# PIC32MX274F256B device description
Architecture: MIPS; Family: PIC32MX; Series: PIC32MX
Registers are 32-bit, read-write, no defined reset value unless marked. A register's access mark holds for its fields unless they carry their own. Offsets are from the block's base; [hi:lo] are bit positions; {n}, {i} and the like mark numbered series; 'fields as' and 'values as' point back to an identical list.

## USB
Instances: USB 0x1f885040 in periph2
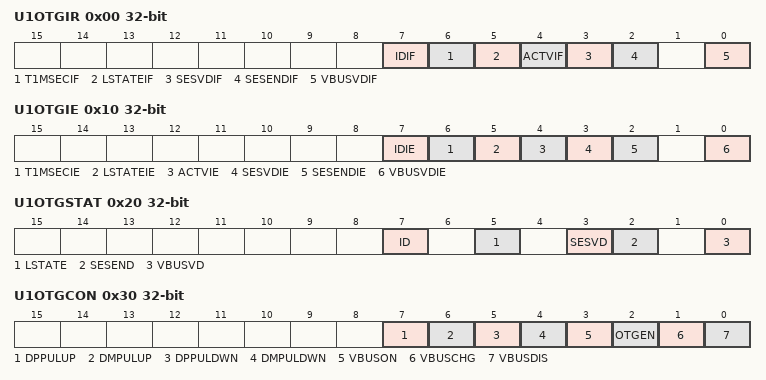
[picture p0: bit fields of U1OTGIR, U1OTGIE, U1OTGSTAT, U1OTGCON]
0x00 U1OTGIR — USB OTG Interrupt Status Register
  [7] IDIF — ID State Change Indicator bit
    1=Change in ID state is detected; 0=No change in ID state is detected
  [6] T1MSECIF — 1 Millisecond Timer bit
    1=1 millisecond timer has expired; 0=1 millisecond timer has not expired
  [5] LSTATEIF — Line State Stable Indicator bit
    1=USB line state has been stable for 1millisecond; 0=USB line state has not been stable for 1 millisecond
  [4] ACTVIF — Bus Activity Indicator bit
    1=Activity on the D+, D-, ID or VBUS pins has caused the device to wake-up; 0=Activity has not been detected
  [3] SESVDIF — Session Valid Change Indicator bit
    1=VBUS voltage has dropped below the session end level; 0=Vbus voltage has not dropped below the session end level
  [2] SESENDIF — B-Device Vbus Change Indicator bit
    1=A change on the session end input was detected; 0=No change on the session end input was detected
  [0] VBUSVDIF — A-Device Vbus Change Indicator bit
    1=Change on the session valid input is detected; 0=No change on the session valid input is detected
0x10 U1OTGIE — USB OTG Interrupt Enable Register
  [7] IDIE — ID Interrupt Enable bit
    1=ID interrupt is enabled; 0=ID interrupt is disabled
  [6] T1MSECIE — 1 Millisecond Timer Interrupt Enable bit
    1=1 millisecond timer interrupt is enabled; 0=1 millisecond timer interrupt is disabled
  [5] LSTATEIE — Line State Interrupt Enable bit
    1=Line state interrupt is enabled; 0=Line state interrupt is disabled
  [4] ACTVIE — Bus Activity Interrupt Enable bit
    1=ACTIVITY interrupt is enabled; 0=ACTIVITY interrupt is disabled
  [3] SESVDIE — Session Valid Interrupt Enable bit
    1=Session valid interrupt is enabled; 0=Session valid interrupt is disabled
  [2] SESENDIE — B-Session End Interrupt Enable bit
    1=B-session end interrupt is enabled; 0=B-session end interrupt is disabled
  [0] VBUSVDIE — A- Vbus Valid Interrupt Enable bit
    1=A-VBUS valid interrupt is enabled; 0=A-VBUS valid interrupt is disabled
0x20 U1OTGSTAT — USB OTG Status Register
  [7] ID — ID Pin State Indicator bit
    1=No cable is attached or a Type-B cable has been plugged into the USB receptacle; 0=A Type-A cable has been plugged into the USB receptacle
  [5] LSTATE — Line State Stable Indicator bit
    1=USB line state (U1CON(SE0) and U1CON(JSTATE)) has been stable for the previous 1 ms; 0=USB line state (U1CON(SE0) and U1CON(JSTATE)) has not been stable for the previous 1 ms
  [3] SESVD — Session Valid Indicator bit
    1=Vbus voltage is above Session Valid on the A or B device; 0=Vbus voltage is below Session Valid on the A or B device
  [2] SESEND — B-Device Session End Indicator bit
    1=Vbus voltage is below Session Valid on the B device; 0=Vbus voltage is above Session Valid on the B device
  [0] VBUSVD — A-Device Vbus Valid Indicator bit
    1=Vbus voltage is above Session Valid on the A device; 0=Vbus voltage is below Session Valid on the A device
0x30 U1OTGCON — USB OTG Control Register
  [7] DPPULUP — D+ Pull-Up Enable bit
    1=D+ data line pull-up resistor is enabled; 0=D+ data line pull-up resistor is disabled
  [6] DMPULUP — D- Pull-Up Enable bit
    1=D- data line pull-up resistor is enabled; 0=D- data line pull-up resistor is disabled
  [5] DPPULDWN — D+ Pull-Down Enable bit
    1=D+ data line pull-down resistor is enabled; 0=D+ data line pull-down resistor is disabled
  [4] DMPULDWN — D- Pull-Down Enable bit
    1=D- data line pull-down resistor is enabled; 0=D- data line pull-down resistor is disabled
  [3] VBUSON — VBUS Power-on bit
    1=VBUS line is powered; 0=VBUS line is not powered
  [2] OTGEN — OTG Functionality Enable bit
    1=DPPULUP, DMPULUP, DPPULDWN and DMPULDWN bits are under software control; 0=DPPULUP, DMPULUP, DPPULDWN and DMPULDWN bits are under USB hardware control
  [1] VBUSCHG — VBUS Charge Enable bit
    1=VBUS line is charged through a pull-up resistor; 0=VBUS line is not charged through a resistor
  [0] VBUSDIS — VBUS Discharge Enable bit
    1=VBUS line is discharged through a pull-down resistor; 0=VBUS line is not discharged through a resistor
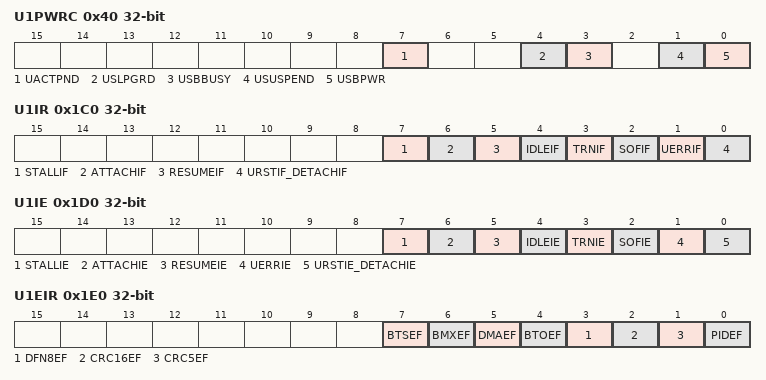
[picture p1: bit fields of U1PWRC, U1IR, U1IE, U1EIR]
0x40 U1PWRC — USB Power Control Register
  [7] UACTPND — USB Activity Pending bit
    1=USB bus activity has been detected; but an interrupt is pending; 0=An interrupt is not pending
  [4] USLPGRD — USB Sleep Entry Guard bit
    1=Sleep entry is blocked if USB bus activity is detected or if a notification is pending; 0=USB module does not block Sleep entry
  [3] USBBUSY — USB Module Busy bit
    1=USB module is active or disabled; 0=USB module is not active and is ready to be enabled
  [1] USUSPEND — USB Suspend Mode bit
    1=USB module is placed in Suspend mode; 0=USB module operates normally
  [0] USBPWR — USB Operation Enable bit
    1=USB module is turned on; 0=USB module is disabled
0x1C0 U1IR — USB Interrupt Register
  [7] STALLIF — STALL Handshake Interrupt bit
    1=(In Host mode) a STALL handshake was received during the handshake phase of the transaction / (In Device mode) a STALL handshake was transmitted during the handshake phase of the transaction; 0=STALL handshake has not been sent
  [6] ATTACHIF — Peripheral Attach Interrupt bit
    1=Peripheral attachment was detected by the USB module; 0=Peripheral attachment was not detected
  [5] RESUMEIF — Resume Interrupt bit
    1=K-State is observed on the D+ or D- pin for 2.5 usec; 0=K-State is not observed
  [4] IDLEIF — Idle Detect Interrupt bit
    1=Idle condition detected (constant Idle state of 3 ms or more); 0=No Idle condition detected
  [3] TRNIF — Token Processing Complete Interrupt bit
    1=Processing of current token is complete; a read of the U1STAT register will provide endpoint information; 0=Processing of current token not complete
  [2] SOFIF — SOF Token Interrupt bit
    1=SOF token received by the peripheral or the SOF threshold reached by the host; 0=SOF token was not received nor threshold reached
  [1] UERRIF — USB Error Condition Interrupt bit
    1=Unmasked error condition has occurred; 0=Unmasked error condition has not occurred
  [0] URSTIF_DETACHIF
0x1D0 U1IE — USB Interrupt Enable Register
  [7] STALLIE — STALL Handshake Interrupt Enable bit
    1=STALL interrupt is enabled; 0=STALL interrupt is disabled
  [6] ATTACHIE — ATTACH Interrupt Enable bit
    1=ATTACH interrupt is enabled; 0=ATTACH interrupt is disabled
  [5] RESUMEIE — RESUME Interrupt Enable bit
    1=RESUME interrupt is enabled; 0=RESUME interrupt is disabled
  [4] IDLEIE — Idle Detect Interrupt Enable bit
    1=Idle interrupt is enabled; 0=Idle interrupt is disabled
  [3] TRNIE — Token Processing Complete Interrupt Enable bit
    1=TRNIF interrupt is enabled; 0=TRNIF interrupt is disabled
  [2] SOFIE — SOF Token Interrupt Enable bit
    1=SOFIF interrupt is enabled; 0=SOFIF interrupt is disabled
  [1] UERRIE — USB Error Interrupt Enable bit
    1=USB Error interrupt is enabled; 0=USB Error interrupt is disabled
  [0] URSTIE_DETACHIE
0x1E0 U1EIR — USB Error Interrupt Status Register
  [7] BTSEF — Bit Stuff Error Flag bit
    1=Packet is rejected due to bit stuff error; 0=Packet is accepted
  [6] BMXEF — Bus Matrix Error Flag bit
    1=The base address, of the BDT, or the address of an individual buffer pointed to by a BDT entry, i s invalid; 0=No address error
  [5] DMAEF — DMA Error Flag bit
    1=USB DMA error condition detected; 0=No DMA error
  [4] BTOEF — Bus Turnaround Time-Out Error Flag bit
    1=Bus turnaround time-out has occurred; 0=No bus turnaround time-out
  [3] DFN8EF — Data Field Size Error Flag bit
    1=Data field received is not an integral number of bytes; 0=Data field received is an integral number of bytes
  [2] CRC16EF — CRC16 Failure Flag bit
    1=Data packet rejected due to CRC16 error; 0=Data packet accepted
  [1] CRC5EF
  [0] PIDEF — PID Check Failure Flag bit
    1=PID check is failed; 0=PID check is passed
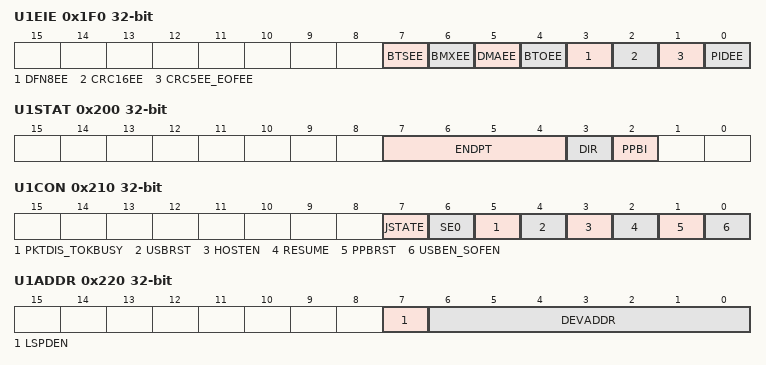
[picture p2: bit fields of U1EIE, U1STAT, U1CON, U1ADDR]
0x1F0 U1EIE — USB Error Interrupt Enable Register
  [7] BTSEE — Bit Stuff Error Interrupt Enable bit
    1=BTSEF interrupt is enabled; 0=BTSEF interrupt is disabled
  [6] BMXEE — Bus Matrix Error Interrupt Enable bit
    1=BMXEF interrupt is enabled; 0=BMXEF interrupt is disabled
  [5] DMAEE — DMA Error Interrupt Enable bit
    1=DMAEF interrupt is enabled; 0=DMAEF interrupt is disabled
  [4] BTOEE — Bus Turnaround Time-out Error Interrupt Enable bit
    1=BTOEF interrupt is enabled; 0=BTOEF interrupt is disabled
  [3] DFN8EE — Data Field Size Error Interrupt Enable bit
    1=DFN8EF interrupt is enabled; 0=DFN8EF interrupt is disabled
  [2] CRC16EE — CRC16 Failure Interrupt Enable bit
    1=CRC16EF interrupt is enabled; 0=CRC16EF interrupt is disabled
  [1] CRC5EE_EOFEE
  [0] PIDEE — PID Check Failure Interrupt Enable bit
    1=PIDEF interrupt is enabled; 0=PIDEF interrupt is disabled
0x200 U1STAT ro — USB Status Register
  [7:4] ENDPT — Encoded Number of Last Endpoint Activity bits
    {v}=Endpoint {v} (v=0..15)
  [3] DIR — Last BD Direction Indicator bit
    1=Last transaction was a transmit transfer (TX); 0=Last transaction was a receive transfer (RX)
  [2] PPBI — Ping-Pong BD Pointer Indicator bit
    1=The last transaction was to the ODD BD bank; 0=The last transaction was to the EVEN BD bank
0x210 U1CON — USB Control Register
  [7] JSTATE — Live Differential Receiver JSTATE flag bit
    1=JSTATE detected on the USB; 0=No JSTATE detected
  [6] SE0 — Live Single-Ended Zero flag bit
    1=Single Ended Zero detected on the USB; 0=No Single Ended Zero detected
  [5] PKTDIS_TOKBUSY
  [4] USBRST — Module Reset bit
    1=USB reset is generated; 0=USB reset is terminated
  [3] HOSTEN — Host Mode Enable bit
    1=USB host capability is enabled; 0=USB host capability is disabled
  [2] RESUME — RESUME Signaling Enable bit
    1=RESUME signaling is activated; 0=RESUME signaling is disabled
  [1] PPBRST — Ping-Pong Buffers Reset bit
    1=Reset all Even/Odd buffer pointers to the EVEN BD banks; 0=Even/Odd buffer pointers not being Reset
  [0] USBEN_SOFEN
0x220 U1ADDR — USB Address Register
  [7] LSPDEN — Low Speed Enable Indicator bit
    1=Next token command to be executed at Low Speed; 0=Next token command to be executed at Full Speed
  [6:0] DEVADDR — 7-bit USB Device Address bits
    127=Device address is 0x7f; 0=Device address is 0
0x230 U1BDTP1 — USB BDT Page 1 Register
  [7:1] BDTPTRL
0x240 U1FRML ro — USB Frame Number Low Register
  [7:0] FRML
0x250 U1FRMH ro — USB Frame Number High Register
  [2:0] FRMH
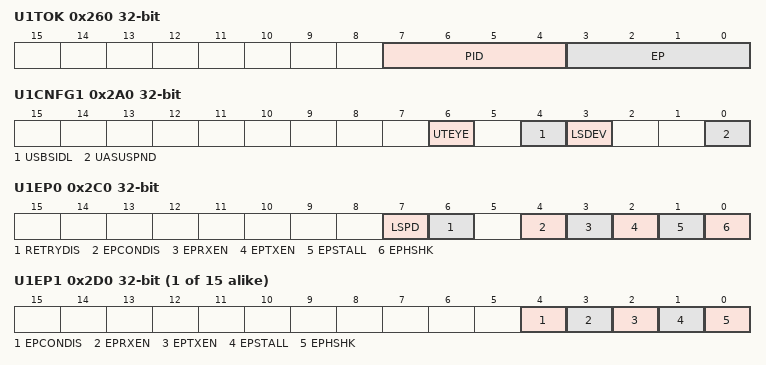
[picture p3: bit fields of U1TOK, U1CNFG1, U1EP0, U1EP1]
0x260 U1TOK — USB Token Register
  [7:4] PID — Token Type Indicator bits
    1=OUT (TX) token type transaction; 9=IN (RX) token type transaction; 13=SETUP (TX) token type transaction
  [3:0] EP — Token Command Endpoint Address bits
    0=Endpoint address is 0
0x270 U1SOF — USB SOF Threshold Register
  [7:0] CNT — SOF Threshold Value bits
    74=64-byte packet; 42=32-byte packet; 26=16-byte packet; 18=8-byte packet
0x280 U1BDTP2 — USB BDT PAGE 2 Register
  [7:0] BDTPTRH — BDT Base Address bits
    0=BDT base address is 0
0x290 U1BDTP3 — USB BDT PAGE 3 Register
  [7:0] BDTPTRU — BDT Base Address bits
    0=BDT base address is 0
0x2A0 U1CNFG1 — USB Configuration 1 Register
  [6] UTEYE — USB Eye-Pattern Test Enable bit
    2=Eye-Pattern Test is enabled; 0=Eye-Pattern Test is disabled
  [4] USBSIDL — Stop in Idle Mode bit
    1=Discontinue module operation when device enters Idle mode; 0=Continue module operation in Idle mode
  [3] LSDEV — Low-Speed Device Enable bit
    1=USB module operates in Low-Speed Device mode only; 0=USB module operates in OTG, Host, or Full-Speed Device mode
  [0] UASUSPND — Automatic Suspend Enable bit
    1=USB module automatically suspends upon entry to Sleep mode; 0=USB module does not automatically suspend upon entry to Sleep mode
0x2C0 U1EP0 — USB Endpoint 0 Control Register
  [7] LSPD — Low-Speed Direct Connection Enable bit (Host mode and U1EP0 only)
    1=Direct connection to a low-speed device is enabled; 0=Direct connection to a low-speed device is disabled; hub required with PRE_PID
  [6] RETRYDIS — Retry Disable bit (Host mode and U1EP0 only)
    1=Retry NAKed transactions is disabled; 0=Retry NAKed transactions is enabled; retry done in hardware
  [4] EPCONDIS — Bidirectional Endpoint Control bit
    1=Disable Endpoint n from Control transfers; only TX and RX transfers allowed; 0=Enable Endpoint n for Control (SETUP) transfers; TX and RX transfers also allowed
  [3] EPRXEN — Endpoint Receive Enable bit
    1=Endpoint n receive is enabled; 0=Endpoint n receive is disabled
  [2] EPTXEN — Endpoint Transmit Enable bit
    1=Endpoint n transmit is enabled; 0=Endpoint n transmit is disabled
  [1] EPSTALL — Endpoint Stall Status bit
    1=Endpoint n was stalled; 0=Endpoint n was not stalled
  [0] EPHSHK — Endpoint Handshake Enable bit
    1=Endpoint Handshake is enabled; 0=Endpoint Handshake is disabled (typically used for isochronous endpoints)
{0x2C0+0x10*i} U1EP{i} (i=1..15) — USB Endpoint {i} Control Register
  [4] EPCONDIS — Bidirectional Endpoint Control bit
    values as U1EP0.EPCONDIS
  [3] EPRXEN — Endpoint Receive Enable bit
    values as U1EP0.EPRXEN
  [2] EPTXEN — Endpoint Transmit Enable bit
    values as U1EP0.EPTXEN
  [1] EPSTALL — Endpoint Stall Status bit
    1=Endpoint n was stalled; 0=Endpoint n was not stalled
  [0] EPHSHK — Endpoint Handshake Enable bit
    values as U1EP0.EPHSHK
Value list U1IR__DETACHIF: 1=Peripheral detachment was detected by the USB module; 0=Peripheral detachment was not detected
Value list U1IR__URSTIF: 1=Valid USB Reset has occurred; 0=No USB Reset has occurred
Value list U1IE__DETACHIE: 1=DATTCHIF interrupt is enabled; 0=DATTCHIF interrupt is disabled
Value list U1IE__URSTIE: 1=URSTIF interrupt is enabled; 0=URSTIF interrupt is disabled
Value list U1EIR__CRC5EF: 2=Token packet is rejected due to CRC5 error; 0=Token packet is accepted; 2=EOF error condition is detected; 0=No EOF error condition
Value list U1EIE__CRC5EE: 2=CRC5EF interrupt is enabled; 0=CRC5EF interrupt is disabled
Value list U1CON__USBEN: 1=(Device mode) USB module and supporting circuitry is enabled / (Host mode) SOF token sent every 1 ms; 0=(Device mode) USB module and supporting circuitry is disabled / (Host mode) SOF token is disabled
